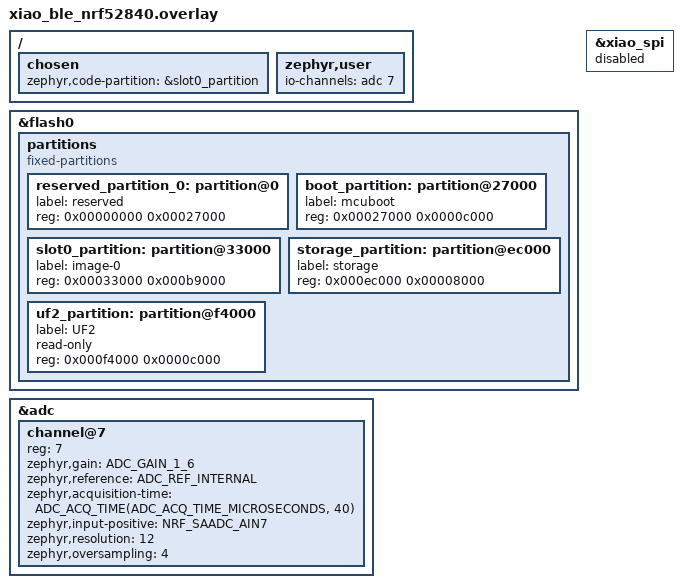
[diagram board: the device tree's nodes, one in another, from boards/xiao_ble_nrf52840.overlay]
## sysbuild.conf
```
# [SECURITY] MCUboot — the Zephyr counterpart to Secure Boot V2 on ESP32 Tag.
# Single-slot mode: MCUboot only verifies the signature and boots
# slot0_partition. OTA over BLE is not supported yet (updates = re-flash
# the whole UF2 via the pre-installed Adafruit bootloader, see
# boards/xiao_ble_nrf52840.overlay for why the layout is this way).
SB_CONFIG_BOOTLOADER_MCUBOOT=y
SB_CONFIG_MCUBOOT_MODE_SINGLE_APP=y
SB_CONFIG_BOOT_SIGNATURE_TYPE_ECDSA_P256=y
SB_CONFIG_BOOT_SIGNATURE_KEY_FILE="../../mcuboot_keys/bmt_tag_ecdsa_p256.pem"
```

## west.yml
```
# Freestanding Zephyr application manifest. Lets `west init -l .` set up
# a workspace that pulls in upstream Zephyr next to this app, without
# requiring the whole nRF Connect SDK.
manifest:
  self:
    path: apps/Beacon_XiaoNrf52840
  remotes:
    - name: zephyrproject
      url-base: https://github.com/zephyrproject-rtos
  projects:
    - name: zephyr
      remote: zephyrproject
      revision: v4.0.0
      import:
        name-allowlist:
          - hal_nordic
          - mcuboot
          - cmsis
          - segger
          - tinycrypt
```

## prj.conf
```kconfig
CONFIG_BT=y
CONFIG_BT_DEVICE_NAME="Test beacon"

# PSA Crypto (HMAC-SHA256) — needed by bmt_auth for epoch key rotation.
CONFIG_PSA_CRYPTO=y
CONFIG_PSA_WANT_ALG_HMAC=y
CONFIG_PSA_WANT_ALG_SHA_256=y
CONFIG_PSA_WANT_KEY_TYPE_HMAC=y

# [POWER] Drop the radio TX power from the default 0 dBm to -4 dBm. Cuts
# current at TX (also reduces the current pulse amplitude through the
# diode / cap — see bmt_battery.c and the CR2032 sag discussion), at the
# cost of slightly shorter range — re-verify real-world distance after
# flashing.
CONFIG_BT_CTLR_TX_PWR_MINUS_4=y

# [POWER] Read the battery via the internal SAADC (VDD) — see bmt_battery.c.
CONFIG_ADC=y

# =====================================================================
# [POWER] Disable USB + CONSOLE + LOG — the largest single saving (~0.7-0.8 mA)
# =====================================================================
#
# First tried disabling USB on this board by picking off individual
# symbols (CONFIG_CONSOLE / UART_CONSOLE / SERIAL=n one at a time) and hit
# a build error: "undefined reference __device_dts_ord_125" in
# log_backend_uart.c — because CONFIG_LOG stayed on, the log backend was
# still compiled, but the UART device had been dropped from devicetree.
# Left this OFF for a while because of that error.
#
# After the ProMicro variant measured and confirmed the right switch
# (see prj.conf in Beacon_ProMicroNrf52840, ~0.7 mA of ~1.9 mA total),
# apply the same fix here: turn off BOTH
# CONFIG_BOARD_SERIAL_BACKEND_CDC_ACM AND CONFIG_LOG at the same time
# (do not split), because CONFIG_LOG=n is what drops log_backend_uart.c
# from the build and avoids the earlier undefined-reference error.
#
# DEBUG NOTE: turning these off means NO COM port and NO log. When you
# need logs, build with debug.conf to bring them back (see README, Build).
CONFIG_BOARD_SERIAL_BACKEND_CDC_ACM=n
CONFIG_LOG=n

# [POWER] APPROACH A (continuous low-power advertising):
#  - CPU auto-sleeps (System ON idle) between transmits: Zephyr's idle
#    thread handles this — no config needed.
#  - DC/DC regulator: ALREADY ENABLED via the board devicetree (reg1 =
#    DCDC mode); nRF52's soc.c reads that property and calls
#    nrf_power_dcdcen_set(true) at boot, so NO extra config here.
#    (Verified against soc/nordic/nrf52/soc.c.)
#  - 1 s interval (bmt_config.h) and TX -4 dBm already set.
# => Approach A is close to optimal by construction; real current
#    measurement needs a Power Profiler (PPK2).
```

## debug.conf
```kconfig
# =====================================================================
# DEBUG BUILD — re-enable console / log over USB CDC-ACM
# =====================================================================
#
# prj.conf (production) DISABLES USB + console + log because they draw
# ~0.7-0.8 mA continuously even after the USB cable is unplugged —
# see the full explanation in prj.conf.
#
# This file re-enables them so you can read logs for debugging. DO NOT
# USE FOR CURRENT MEASUREMENT: the reading will be ~0.7-0.8 mA higher
# than the real firmware.
#
# Build command:
#   west build -b xiao_ble/nrf52840 -d build_debug . --pristine \
#       -- "-DBeacon_XiaoNrf52840_EXTRA_CONF_FILE=debug.conf"
#
# (The "Beacon_XiaoNrf52840_" prefix is required — this is a sysbuild
#  multi-image build; without the prefix CMake configure will fail.)

# Re-enable the switch that prj.conf turned off. This drags in the
# whole cluster: SERIAL, CONSOLE, UART_CONSOLE, USB_DEVICE_STACK_NEXT,
# CDC_ACM_SERIAL_INITIALIZE_AT_BOOT (see prj.conf for the detail).
#
# NOTE: setting only CONFIG_CONSOLE=y / SERIAL=y without this line is
# USELESS — the console comes up but there is no UART device to send
# output to, so no COM port appears. (Been caught by this once on
# ProMicro.)
CONFIG_BOARD_SERIAL_BACKEND_CDC_ACM=y
CONFIG_LOG=y

# Bump the USB buffer pool to avoid "udc: Failed to allocate net_buf N"
# when USB control transactions and CDC-ACM log traffic overlap (after
# SUSPEND / RESUME).
CONFIG_UDC_BUF_POOL_SIZE=4096
CONFIG_UDC_BUF_COUNT=32
```

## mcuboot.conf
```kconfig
# [SECURITY] MCUboot on nRF52840 boards uses USB CDC-ACM as its default
# console (the board has no dedicated debug UART), but MCUboot does NOT
# enable the USB stack (minimal bootloader, does not need it). Result:
# missing driver link -> "undefined reference to __device_dts_ord_N".
# MCUboot has nothing useful to print anyway (only verifies signature
# and jumps to slot0_partition), so disabling the console is the
# simplest fix — and reduces attack surface (no version / debug info
# leaked over serial).
CONFIG_UART_CONSOLE=n
CONFIG_CONSOLE=n
```

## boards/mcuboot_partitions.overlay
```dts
/*
 * [SECURITY] Partition copy of xiao_ble_nrf52840.overlay, dedicated
 * to MCUboot's own build (not the "beacon" app).
 *
 * WHY A SEPARATE FILE: Zephyr auto-applies boards/xiao_ble_nrf52840.overlay
 * only to the main app (beacon). MCUboot is a COMPLETELY SEPARATE
 * Zephyr app that sysbuild builds in its own directory
 * (bootloader/mcuboot/boot/zephyr), so the overlay must be passed
 * explicitly via mcuboot_EXTRA_DTC_OVERLAY_FILE (see
 * sysbuild/CMakeLists.txt).
 *
 * DO NOT share a file with the app: "chosen { zephyr,code-partition }"
 * must DIFFER between the two — MCUboot must link into boot_partition
 * (0x27000) while the app must link into slot0_partition (0x33000).
 * Sharing (a single chosen line) would make MCUboot link into
 * slot0_partition and overwrite the app itself — this actually
 * happened during a test build (0x33000 collision between the two
 * .hex files).
 */

/delete-node/ &reserved_partition_0;
/delete-node/ &code_partition;
/delete-node/ &storage_partition;
/delete-node/ &boot_partition;

/ {
	chosen {
		zephyr,code-partition = &boot_partition;
	};
};

&flash0 {
	partitions {
		compatible = "fixed-partitions";
		#address-cells = <1>;
		#size-cells = <1>;

		reserved_partition_0: partition@0 {
			label = "reserved";
			reg = <0x00000000 0x00027000>;
		};

		boot_partition: partition@27000 {
			label = "mcuboot";
			reg = <0x00027000 0x0000c000>;
		};

		slot0_partition: partition@33000 {
			label = "image-0";
			reg = <0x00033000 0x000b9000>;
		};

		storage_partition: partition@ec000 {
			label = "storage";
			reg = <0x000ec000 0x00008000>;
		};

		uf2_partition: partition@f4000 {
			label = "UF2";
			read-only;
			reg = <0x000f4000 0x0000c000>;
		};
	};
};
```

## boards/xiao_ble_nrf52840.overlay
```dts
/*
 * [SECURITY] MCUboot partition layout — Tag nRF52840.
 *
 * XIAO nRF52840 ships from the factory with the Adafruit UF2
 * bootloader (no SWD / J-Link is exposed; the only way to reflash
 * is UF2 mass storage). That bootloader lives at a FIXED high
 * address (0xF4000-0x100000, see nrf52840_partition_uf2_sdv7.dtsi
 * in Zephyr) and is jumped to directly by the CPU from
 * UICR.BOOTLOADERADDR at power-on — DO NOT touch this region, it
 * is the only recovery path if MCUboot / app is broken (you can
 * still drag-and-drop a fresh UF2 as usual).
 *
 * Once the Adafruit bootloader finishes it jumps to address
 * 0x27000 (the "Application" address hardcoded in the bootloader,
 * intended for SoftDevice s140 v7 — Zephyr does not use SoftDevice,
 * but must still boot at that fixed offset). So instead of putting
 * the app directly at 0x27000 as before, place MCUboot
 * (boot_partition) there — MCUboot becomes the "second-stage"
 * bootloader, chain-loaded by the Adafruit bootloader, then
 * verifies the signature and jumps to slot0_partition (the real
 * app).
 *
 * New layout:
 *   0x00000 - 0x27000  reserved         (unused, kept for historical meaning)
 *   0x27000 - 0x33000  boot_partition   (MCUboot, 48 KB)
 *   0x33000 - 0xEC000  slot0_partition  (app, ~741 KB — single-slot
 *                                        mode; no slot1 yet because
 *                                        BLE OTA is not implemented,
 *                                        updates = full UF2 reflash)
 *   0xEC000 - 0xF4000  storage_partition (32 KB, kept at old address)
 *   0xF4000 - 0x100000 uf2_partition    (Adafruit bootloader — UNTOUCHED)
 */

/delete-node/ &reserved_partition_0;
/delete-node/ &code_partition;
/delete-node/ &storage_partition;
/delete-node/ &boot_partition;

/ {
	chosen {
		zephyr,code-partition = &slot0_partition;
	};

	/* [POWER] Read battery via the ON-BOARD battery measurement
	 * path (for a cell wired into BAT+ / BAT- — LIR2032 3.6 V or
	 * LiPo).
	 *
	 * Different from reading VDD (only valid for a CR2032 wired
	 * straight to 3V3): when the cell feeds through BAT+ into the
	 * on-board regulator, VDD is pinned at ~3.3 V and does NOT
	 * reflect the true battery voltage. So the voltage at the
	 * BAT+ node must be read through the on-board 1M / 510k
	 * divider brought out to P0.31 (AIN7).
	 *
	 * P0.14 (VBAT_ENABLE, active-low) must be driven LOW to
	 * "close" the divider into the measurement path (see
	 * bmt_battery.c). Kept LOW for the whole lifetime — the
	 * divider leaks ~2.6 uA continuously, acceptable. MUST NOT be
	 * HIGH: P0.31 can then overshoot to 3.6 V (pin limit) — the
	 * official Seeed warning. */
	zephyr,user {
		io-channels = <&adc 7>;
	};
};

&flash0 {
	partitions {
		compatible = "fixed-partitions";
		#address-cells = <1>;
		#size-cells = <1>;

		reserved_partition_0: partition@0 {
			label = "reserved";
			reg = <0x00000000 0x00027000>;
		};

		boot_partition: partition@27000 {
			label = "mcuboot";
			reg = <0x00027000 0x0000c000>;
		};

		slot0_partition: partition@33000 {
			label = "image-0";
			reg = <0x00033000 0x000b9000>;
		};

		storage_partition: partition@ec000 {
			label = "storage";
			reg = <0x000ec000 0x00008000>;
		};

		uf2_partition: partition@f4000 {
			label = "UF2";
			read-only;
			reg = <0x000f4000 0x0000c000>;
		};
	};
};

/* [POWER] Disable SPI2 (xiao_spi) — the board enables it by
 * default but the firmware uses no SPI. (Historical note: first
 * disable attempt was thought to have hung the board, but the real
 * cause was flashing an UNSIGNED app image — MCUboot refused it.
 * Disabling SPI2 is harmless. Remember to flash with the
 * signed-merge output, see _fw_backup.) */
&xiao_spi {
	status = "disabled";
};

&adc {
	#address-cells = <1>;
	#size-cells = <0>;

	/* Channel 7 = P0.31 (AIN7) = output of the BAT+ on-board divider.
	 * Gain 1/6 + internal reference (0.6 V) -> input range 0..3.6 V,
	 * enough for the divided voltage (BAT+ 4.2 V / ~3.0 = ~1.4 V,
	 * comfortably inside the range). */
	channel@7 {
		reg = <7>;
		zephyr,gain = "ADC_GAIN_1_6";
		zephyr,reference = "ADC_REF_INTERNAL";
		/* The on-board divider has a source impedance of ~342 k
		 * (1037k || 510k) — VERY HIGH for the SAADC. Acquisition
		 * time MUST be 40 us (the SAADC maximum) so the
		 * sample-and-hold cap can charge fully -> accurate
		 * reading. At the DEFAULT 10 us, readings are off by
		 * several hundred mV (observed: firmware 3.88 V vs DMM
		 * 3.27 V). */
		zephyr,acquisition-time = <ADC_ACQ_TIME(ADC_ACQ_TIME_MICROSECONDS, 40)>;
		zephyr,input-positive = <NRF_SAADC_AIN7>;
		zephyr,resolution = <12>;
		zephyr,oversampling = <4>;
	};
};
```

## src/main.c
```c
#include <zephyr/kernel.h>
#include <zephyr/sys/printk.h>
#include <zephyr/logging/log.h>

#include <zephyr/bluetooth/bluetooth.h>

#include "bmt_auth.h"
#include "bmt_beacon.h"
#include "bmt_battery.h"

LOG_MODULE_REGISTER(bmt_main, LOG_LEVEL_INF);

static void bt_ready(int err)
{
	if (err)
	{
		LOG_ERR("Bluetooth init failed (err %d)", err);
		return;
	}
	LOG_INF("Bluetooth initialized");

	/* MUST be called before bmt_beacon_start() — the beacon needs
	 * the HMAC key ready so it can compute mac16 for the very
	 * first ADV. */
	bmt_auth_init();

	err = bmt_beacon_start();
	if (err)
	{
		LOG_ERR("bmt_beacon_start failed (err %d)", err);
		return;
	}
	LOG_INF("BMT Tag beacon started");
}

int main(void)
{
	printk("=== BMT Tag (nRF52840) starting ===\n");

	/* Battery reading has nothing to do with BLE, start it in
	 * parallel with bt_enable. */
	int batt_err = bmt_battery_init();
	if (batt_err)
	{
		LOG_ERR("bmt_battery_init failed (err %d)", batt_err);
	}

	int err = bt_enable(bt_ready);
	if (err)
	{
		LOG_ERR("bt_enable failed (err %d)", err);
	}
	return 0;
}
```

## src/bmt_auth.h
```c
#pragma once

#include <stddef.h>
#include <stdint.h>

/* Goi 1 lan luc boot, TRUOC lan build_adv_data() dau tien */
void bmt_auth_init(void);

/* Tinh HMAC-16 tren payload — dung khi build goi ADV moi lan sequence++ */
uint16_t bmt_auth_hmac16(const uint8_t* data, size_t len);
```

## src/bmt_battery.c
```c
#include "bmt_battery.h"

#include <zephyr/kernel.h>
#include <zephyr/device.h>
#include <zephyr/devicetree.h>
#include <zephyr/drivers/adc.h>
#include <zephyr/drivers/gpio.h>
#include <zephyr/logging/log.h>

LOG_MODULE_REGISTER(bmt_battery, LOG_LEVEL_INF);

/* [POWER] Read the battery over the BAT+ / BAT- rail (LIR2032 3.6 V
 * or LiPo).
 *
 * Why NOT read VDD directly: when the cell feeds through the
 * on-board regulator, VDD is pinned at ~3.3 V regardless of whether
 * the cell is at 4.2 V or 3.4 V — so reading VDD tells us nothing
 * useful. Read the voltage at the BAT+ node through the on-board
 * 1M/510k divider brought out to P0.31 (AIN7). Formula and resistor
 * values follow the Tjoms99/xiao_sense_nrf52840_battery_lib
 * community library (verified on real hardware).
 *
 * (If later switching back to a CR2032 wired straight to 3V3,
 * change this to read NRF_SAADC_VDD in the overlay and drop the
 * divider — different supply, different measurement path.) */
static const struct adc_dt_spec battery_adc = ADC_DT_SPEC_GET_BY_IDX(DT_PATH(zephyr_user), 0);

/* On-board divider: BAT+ --[R1]-- P0.31 --[R2]-- (P0.14 pulls GND).
 * V_bat = V_adc * (R1 + R2) / R2. Nominal 1M / 510k; R1 is set to
 * 1037k per the empirical calibration from the reference library
 * (resistor tolerance). For higher accuracy, measure real V_bat
 * with a DMM and recompute R1. */
#define BMT_BATT_R1_KOHM 1037
#define BMT_BATT_R2_KOHM 510

/* P0.14 = VBAT_ENABLE (active-low): drive LOW to close the divider
 * into the measurement path.
 * P0.17 = charge status (LOW while charging). */
static const struct device* gpio0 = DEVICE_DT_GET(DT_NODELABEL(gpio0));
#define BMT_BATT_ENABLE_PIN 14
#define BMT_BATT_CHARGE_STAT_PIN 17

/* Voltage -> percent lookup for Li-ion (LIR2032 / LiPo). The Li-ion
 * SoC-vs-voltage curve is strongly non-linear, so a single linear
 * formula would be wrong across the range — use a table and
 * interpolate between adjacent points. 4200 mV = 100% (full),
 * 3300 mV = 0% (safe cutoff; below this the cell degrades).
 * Curve from the Tjoms99 library and the Nordic SoC blog. */
typedef struct
{
	uint16_t mv;
	uint8_t pct;
} batt_point_t;

static const batt_point_t BATT_CURVE[] = {
    {4200, 100},
    {4110, 90},
    {4020, 80},
    {3930, 70},
    {3840, 60},
    {3750, 50},
    {3660, 40},
    {3570, 30},
    {3480, 20},
    {3390, 10},
    {3300, 0},
};
#define BATT_CURVE_N (sizeof(BATT_CURVE) / sizeof(BATT_CURVE[0]))

#define BMT_BATT_LOG_INTERVAL_SEC 30

static struct k_timer batt_log_timer;
static struct k_work batt_log_work;

/* Cached % — the beacon reads this and embeds it in each ADV
 * (instead of hitting the ADC per packet). Refreshed by the work
 * handler (30 s) and once synchronously during init. */
static uint8_t s_last_percent = 0;

uint8_t bmt_battery_last_percent(void)
{
	return s_last_percent;
}

int bmt_battery_read_mv(void)
{
	int16_t raw = 0;
	struct adc_sequence sequence = {
	    .buffer = &raw,
	    .buffer_size = sizeof(raw),
	};

	int err = adc_sequence_init_dt(&battery_adc, &sequence);
	if (err < 0)
	{
		LOG_ERR("adc_sequence_init_dt failed (%d)", err);
		return err;
	}

	err = adc_read_dt(&battery_adc, &sequence);
	if (err < 0)
	{
		LOG_ERR("adc_read_dt failed (%d)", err);
		return err;
	}

	int32_t adc_mv = raw;
	err = adc_raw_to_millivolts_dt(&battery_adc, &adc_mv);
	if (err < 0)
	{
		LOG_ERR("adc_raw_to_millivolts_dt failed (%d)", err);
		return err;
	}

	/* Reverse the divider ratio to recover the real BAT+ voltage. */
	int32_t vbat = (adc_mv * (BMT_BATT_R1_KOHM + BMT_BATT_R2_KOHM)) / BMT_BATT_R2_KOHM;
	return vbat;
}

uint8_t bmt_battery_percent(int mv)
{
	if (mv >= BATT_CURVE[0].mv)
		return 100;
	if (mv <= BATT_CURVE[BATT_CURVE_N - 1].mv)
		return 0;

	for (size_t i = 0; i < BATT_CURVE_N - 1; i++)
	{
		uint16_t hi = BATT_CURVE[i].mv;
		uint16_t lo = BATT_CURVE[i + 1].mv;
		if (mv <= hi && mv >= lo)
		{
			/* Linear interpolation between the two adjacent points. */
			int pct_hi = BATT_CURVE[i].pct;
			int pct_lo = BATT_CURVE[i + 1].pct;
			return (uint8_t)(pct_lo + ((mv - lo) * (pct_hi - pct_lo)) / (hi - lo));
		}
	}
	return 0;
}

bool bmt_battery_is_charging(void)
{
	/* P0.17 LOW = charging (charger IC pulls it down). */
	return gpio_pin_get(gpio0, BMT_BATT_CHARGE_STAT_PIN) == 0;
}

static void batt_log_work_handler(struct k_work* work)
{
	ARG_UNUSED(work);

	int mv = bmt_battery_read_mv();
	if (mv < 0)
	{
		LOG_ERR("Battery read failed (%d)", mv);
		return;
	}
	s_last_percent = bmt_battery_percent(mv);
	LOG_INF("[BATTERY] BAT+=%d mV (~%u%%) %s", mv, s_last_percent,
	        bmt_battery_is_charging() ? "[CHARGING]" : "");
}

static void batt_log_timer_handler(struct k_timer* timer)
{
	/* k_timer callback runs in ISR context; adc_read may block,
	 * so hand it off to the workqueue. */
	ARG_UNUSED(timer);
	k_work_submit(&batt_log_work);
}

int bmt_battery_init(void)
{
	if (!device_is_ready(gpio0))
	{
		LOG_ERR("gpio0 not ready");
		return -ENODEV;
	}

	/* P0.14 VBAT_ENABLE active-low: OUTPUT_ACTIVE -> drive LOW ->
	 * close the divider into the measurement path. Keep LOW for
	 * the whole lifetime (see the overlay note) — MUST NOT be
	 * HIGH (even briefly): Seeed officially warns that P0.31 can
	 * overshoot the ADC input limit when P0.14 is HIGH. */
	int err = gpio_pin_configure(gpio0, BMT_BATT_ENABLE_PIN,
	                             GPIO_OUTPUT_ACTIVE | GPIO_ACTIVE_LOW);
	if (err < 0)
	{
		LOG_ERR("config VBAT_ENABLE (P0.14) failed (%d)", err);
		return err;
	}

	/* P0.17 charge-status: INPUT to read the charge state. */
	err = gpio_pin_configure(gpio0, BMT_BATT_CHARGE_STAT_PIN, GPIO_INPUT);
	if (err < 0)
	{
		LOG_ERR("config CHARGE_STAT (P0.17) failed (%d)", err);
		return err;
	}

	if (!adc_is_ready_dt(&battery_adc))
	{
		LOG_ERR("ADC device %s not ready", battery_adc.dev->name);
		return -ENODEV;
	}

	err = adc_channel_setup_dt(&battery_adc);
	if (err < 0)
	{
		LOG_ERR("adc_channel_setup_dt failed (%d)", err);
		return err;
	}

	LOG_INF("Battery ADC (BAT+ on-board divider) ready");

	/* Synchronous read once so s_last_percent has a valid value
	 * BEFORE the beacon starts advertising (build_adv_data reads
	 * bmt_battery_last_percent). */
	int mv0 = bmt_battery_read_mv();
	if (mv0 >= 0)
		s_last_percent = bmt_battery_percent(mv0);

	k_work_init(&batt_log_work, batt_log_work_handler);
	k_timer_init(&batt_log_timer, batt_log_timer_handler, NULL);
	k_timer_start(&batt_log_timer, K_SECONDS(BMT_BATT_LOG_INTERVAL_SEC),
	              K_SECONDS(BMT_BATT_LOG_INTERVAL_SEC));

	/* Print once at boot as well. */
	k_work_submit(&batt_log_work);

	return 0;
}
```

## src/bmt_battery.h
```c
#pragma once

#include <stdbool.h>
#include <stdint.h>

/* Initialise the on-board battery-measurement path (P0.14 enable
 * + P0.31 ADC via the on-board voltage divider) for a cell wired
 * to BAT+ / BAT- (LIR2032 / LiPo). See bmt_battery.c for details. */
int bmt_battery_init(void);

/* Read the actual battery voltage at BAT+ (compensating for the
 * divider ratio), in mV. Returns < 0 on error. */
int bmt_battery_read_mv(void);

/* Estimate remaining battery percentage from voltage using a Li-ion
 * lookup curve (interpolated, see BATT_CURVE in bmt_battery.c). 0-100. */
uint8_t bmt_battery_percent(int mv);

/* true when the charger IC is charging (P0.17 LOW). */
bool bmt_battery_is_charging(void);

/* Cached % from the most recent periodic read — used by the beacon
 * to embed in each ADV payload without re-reading the ADC. Refreshed
 * by a 30 s timer in bmt_battery.c and once synchronously at init. */
uint8_t bmt_battery_last_percent(void);
```

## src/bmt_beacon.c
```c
#include "bmt_beacon.h"

#include <string.h>

#include <zephyr/kernel.h>
#include <zephyr/random/random.h>
#include <zephyr/logging/log.h>

#include <zephyr/bluetooth/bluetooth.h>
#include <zephyr/bluetooth/hci.h>

#include "bmt_config.h"
#include "bmt_auth.h"
#include "bmt_types.h"
#include "bmt_battery.h"

LOG_MODULE_REGISTER(bmt_beacon, LOG_LEVEL_INF);

/* Company ID Espressif (0x02E5) — GIU NGUYEN de Scanner (ESP32) hien co
 * van nhan dien duoc tag, du Tag gio chay chip Nordic. Scanner loc theo
 * dung CID nay trong manufacturer data — khong lien quan hang chip that. */
#define BMT_CID_ESPRESSIF 0x02E5

static uint8_t s_sequence = 0;
static bool s_adv_active = false;

/* Buffer manufacturer data = 2 byte CID (little-endian) + 24 byte payload
 * — dung 1 buffer tinh (khong dung stack) vi bt_le_adv_start() doi hoi
 * con tro data hop le tai thoi diem goi, giong cach s_adv_raw ben ESP32. */
static uint8_t s_mfg_data[2 + sizeof(bmt_tag_adv_payload_t)];

static struct k_timer s_seq_timer;
static struct k_work s_seq_work;

static void build_adv_data(void)
{
	bmt_tag_adv_payload_t p;

	memcpy(p.uuid, BMT_SYSTEM_UUID, 16);
	/* Truoc day field nay la major (PERSON/ASSET); gio mang % pin (0-100).
	 * Doc gia tri cache (bmt_battery cap nhat 30s/lan) — khong doc ADC moi
	 * goi ADV de nhe hon cho pin. */
	p.battery = bmt_battery_last_percent();
	p.minor = BMT_TAG_MINOR;
	p.tx_power = BMT_TAG_TX_POWER;
	p.sequence = s_sequence;
	p.mac16 = 0; /* bat buoc = 0 truoc khi tinh HMAC */

	/* HMAC tinh tren tat ca field tru 2 byte mac16 cuoi — GIONG HET
	 * cong thuc ben ESP32, chi khac API goi (bmt_auth_hmac16 dung chung). */
	p.mac16 = bmt_auth_hmac16((uint8_t*)&p, sizeof(p) - sizeof(p.mac16));

	s_mfg_data[0] = (uint8_t)(BMT_CID_ESPRESSIF & 0xFF);
	s_mfg_data[1] = (uint8_t)(BMT_CID_ESPRESSIF >> 8);
	memcpy(s_mfg_data + 2, &p, sizeof(p));
}

static void start_adv_random_interval(void)
{
	/* Random [900, 1100] ms -> tranh collision nhieu tag, GIONG HET ESP32 */
	uint32_t ms = BMT_ADV_INTERVAL_MIN_MS +
	              (sys_rand32_get() % (BMT_ADV_INTERVAL_MAX_MS - BMT_ADV_INTERVAL_MIN_MS + 1));

	/* One-shot: timer fire chinh xac sau "ms" ms — dong bo voi radio interval
	 * hien tai (900-1100ms). Timer auto-reload co dinh 500ms se ke o giua chu
	 * ky radio va bat dau adv_stop/start nham, gay dong trung binh gap doi. */
	k_timer_start(&s_seq_timer, K_MSEC(ms), K_NO_WAIT);

	/* BLE unit = 0.625ms — cung don vi voi ESP-IDF, cong thuc doi giong het */
	uint16_t units = (uint16_t)((ms * 1000) / 625);

	build_adv_data();

	const struct bt_le_adv_param param = {
	    .id = BT_ID_DEFAULT,
	    .sid = 0,
	    .secondary_max_skip = 0,
	    .options = BT_LE_ADV_OPT_USE_IDENTITY, /* dia chi cong khai, khong dung private/random rotating */
	    .interval_min = units,
	    .interval_max = units,
	    .peer = NULL,
	};

	const struct bt_data ad[] = {
	    /* Flags = 0x06 (LE General Discoverable | No BR/EDR) — GIONG HET gia
	     * tri hardcode ben ESP32 */
	    BT_DATA_BYTES(BT_DATA_FLAGS, (BT_LE_AD_GENERAL | BT_LE_AD_NO_BREDR)),
	    BT_DATA(BT_DATA_MANUFACTURER_DATA, s_mfg_data, sizeof(s_mfg_data)),
	};

	int err = bt_le_adv_start(&param, ad, ARRAY_SIZE(ad), NULL, 0);
	if (err)
	{
		LOG_ERR("ADV start FAILED (err %d)", err);
		s_adv_active = false;
		return;
	}
	s_adv_active = true;
	LOG_DBG("ADV OK seq=%u pin=%u%% minor=0x%04X", s_sequence,
	        bmt_battery_last_percent(), BMT_TAG_MINOR);
}

static void seq_work_handler(struct k_work* work)
{
	ARG_UNUSED(work);
	s_sequence++; /* uint8_t: 255 -> 0 tu dong, giong ESP32 */

	bt_le_adv_stop();
	start_adv_random_interval();
}

static void seq_timer_handler(struct k_timer* timer)
{
	/* [QUAN TRONG] k_timer callback chay trong ISR context — KHONG duoc
	 * goi truc tiep bt_le_adv_stop/start o day (co the block, gay loi).
	 * Day cong viec that sang system workqueue qua k_work, giong tinh
	 * than "FreeRTOS timer callback ngan, cong viec nang lam o task rieng"
	 * nhung ESP32 khong bi rang buoc nay chat che nhu Zephyr ISR. */
	ARG_UNUSED(timer);
	k_work_submit(&s_seq_work);
}

int bmt_beacon_start(void)
{
	k_work_init(&s_seq_work, seq_work_handler);

	/* One-shot: chu ky dat lai trong start_adv_random_interval(). */
	k_timer_init(&s_seq_timer, seq_timer_handler, NULL);

	/* Bat dau advertise lan dau — ham nay tu k_timer_start() cho lan dau */
	start_adv_random_interval();

	return 0;
}

uint8_t bmt_beacon_sequence(void)
{
	return s_sequence;
}

bool bmt_beacon_is_active(void)
{
	return s_adv_active;
}

uint16_t bmt_beacon_last_mac16(void)
{
	bmt_tag_adv_payload_t p;
	memcpy(&p, s_mfg_data + 2, sizeof(p));
	return p.mac16;
}
```

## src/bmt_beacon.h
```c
#pragma once

#include <stdbool.h>
#include <stdint.h>

/* Tao timer sequence 500ms, bat dau advertise.
 * PHAI goi SAU khi bt_enable() da thanh cong va bmt_auth_init() da chay. */
int bmt_beacon_start(void);

/* Getter (debug/status) */
uint8_t bmt_beacon_sequence(void);
uint16_t bmt_beacon_last_mac16(void);
bool bmt_beacon_is_active(void);
```

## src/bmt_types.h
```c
#pragma once

#include <stdint.h>

/* PHAI GIONG HET struct ben ESP32 (apps/tag/components/bmt_beacon/bmt_beacon.h)
 * — day la giao dien duy nhat giua Tag va he thong (Scanner/Mesh/Gateway).
 * Sai 1 byte la Scanner tu choi nhan dien tag. */
#pragma pack(1)
typedef struct
{
	uint8_t uuid[16];    /* 16B: system UUID (AB000000-...) */
	uint16_t battery;    /*  2B: % pin con lai (0-100). Truoc day la "major"
	                      *      (PERSON/ASSET) — da bo vi tag deo khong can
	                      *      phan loai, dung 2B nay cho battery. Giu nguyen
	                      *      vi tri/kich thuoc nen HMAC + layout 24B khong doi. */
	uint16_t minor;      /*  2B: tag ID trong he thong */
	int8_t tx_power;     /*  1B: measured power tai 1m (calibrate) */
	uint8_t sequence;    /*  1B: 0-255, wraps -> Scanner tinh loss rate */
	uint16_t mac16;      /*  2B: HMAC-SHA256 rut gon (thay CRC16) */
} bmt_tag_adv_payload_t; /* = 24 bytes */
#pragma pack()
```
